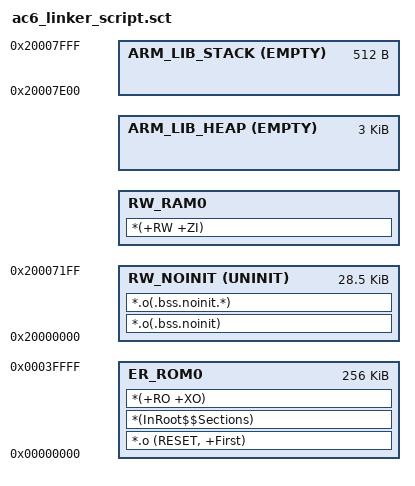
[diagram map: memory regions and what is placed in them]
# 1 "C:/Users/aibar/Downloads/REPOSITORY/Embedded-Control-Robotics-PLC/RTOS/1/Blank_solution/Project0/RTE/Device/TM4C123GH6PM/ac6_linker_script.sct.src"
# 1 "<built-in>" 1
# 1 "<built-in>" 3
# 411 "<built-in>" 3
# 1 "<command line>" 1
# 1 "<built-in>" 2
# 1 "C:/Users/aibar/Downloads/REPOSITORY/Embedded-Control-Robotics-PLC/RTOS/1/Blank_solution/Project0/RTE/Device/TM4C123GH6PM/regions_TM4C123GH6PM.h" 1
# 2 "<built-in>" 2
# 1 "C:/Users/aibar/Downloads/REPOSITORY/Embedded-Control-Robotics-PLC/RTOS/1/Blank_solution/Project0/RTE/Device/TM4C123GH6PM/ac6_linker_script.sct.src" 2
# 32 "C:/Users/aibar/Downloads/REPOSITORY/Embedded-Control-Robotics-PLC/RTOS/1/Blank_solution/Project0/RTE/Device/TM4C123GH6PM/ac6_linker_script.sct.src"
LR_ROM0 0x00000000 0x00040000 {

  ER_ROM0 0x00000000 0x00040000 {
    *.o (RESET, +First)
    *(InRoot$$Sections)
    *(+RO +XO)
  }







  RW_NOINIT 0x20000000 UNINIT (0x00008000 - 0x00000C00 - 0x00000200 - 0) {
    *.o(.bss.noinit)
    *.o(.bss.noinit.*)
  }

  RW_RAM0 AlignExpr(+0, 8) (0x00008000 - 0x00000C00 - 0x00000200 - 0 - AlignExpr(ImageLength(RW_NOINIT), 8)) {
    *(+RW +ZI)
  }


  ARM_LIB_HEAP (AlignExpr(+0, 8)) EMPTY 0x00000C00 { ; Reserve empty region for heap
  }


  ARM_LIB_STACK (0x20000000 + 0x00008000 - 0) EMPTY -0x00000200 { ; Reserve empty region for stack
  }
# 85 "C:/Users/aibar/Downloads/REPOSITORY/Embedded-Control-Robotics-PLC/RTOS/1/Blank_solution/Project0/RTE/Device/TM4C123GH6PM/ac6_linker_script.sct.src"
}
